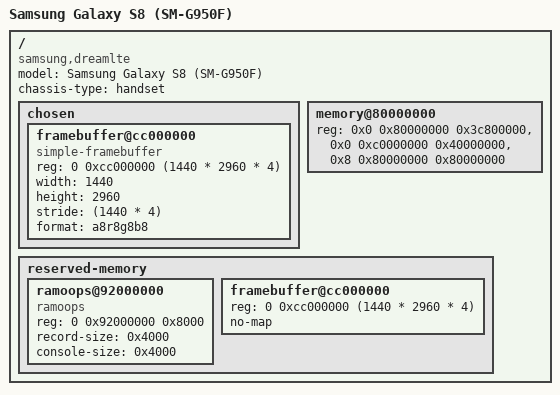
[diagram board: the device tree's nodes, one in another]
// SPDX-License-Identifier: GPL-2.0 OR BSD-3-Clause
/*
 * Samsung Galaxy S8 (dreamlte/SM-G950F) device tree source
 *
 * Copyright (c) 2024, Ivaylo Ivanov <ivo.ivanov.ivanov1@gmail.com>
 */

/dts-v1/;
#include "exynos8895.dtsi"

/ {
	model = "Samsung Galaxy S8 (SM-G950F)";
	compatible = "samsung,dreamlte", "samsung,exynos8895";
	chassis-type = "handset";

	chosen {
		#address-cells = <2>;
		#size-cells = <1>;
		ranges;

		framebuffer@cc000000 {
			compatible = "simple-framebuffer";
			reg = <0 0xcc000000 (1440 * 2960 * 4)>;
			width = <1440>;
			height = <2960>;
			stride = <(1440 * 4)>;
			format = "a8r8g8b8";
		};
	};

	memory@80000000 {
		device_type = "memory";
		reg = <0x0 0x80000000 0x3c800000>,
		      <0x0 0xc0000000 0x40000000>,
		      <0x8 0x80000000 0x80000000>;
	};

	reserved-memory {
		#address-cells = <2>;
		#size-cells = <1>;
		ranges;

		ramoops@92000000 {
			compatible = "ramoops";
			reg = <0 0x92000000 0x8000>;
			record-size = <0x4000>;
			console-size = <0x4000>;
		};

		framebuffer@cc000000 {
			reg = <0 0xcc000000 (1440 * 2960 * 4)>;
			no-map;
		};
	};
};
